VERSION ""

NS_ :

BS_:

BU_:

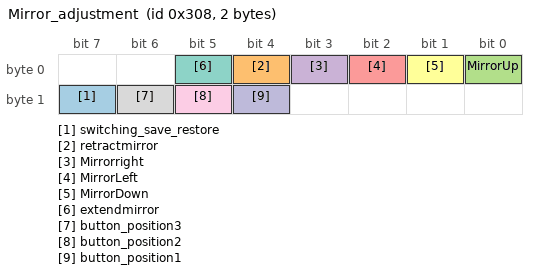
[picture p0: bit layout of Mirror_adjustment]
BO_ 776 Mirror_adjustment: 2 Vector__XXX
 SG_ switching_save_restore : 15|1@1+ (1,0) [0|0] "" Vector__XXX
 SG_ retractmirror : 4|1@1+ (1,0) [0|0] "" Vector__XXX
 SG_ MirrorUp : 0|1@1+ (1,0) [0|0] "" Vector__XXX
 SG_ Mirrorright : 3|1@1+ (1,0) [0|0] "" Vector__XXX
 SG_ MirrorLeft : 2|1@1+ (1,0) [0|0] "" Vector__XXX
 SG_ MirrorDown : 1|1@1+ (1,0) [0|0] "" Vector__XXX
 SG_ extendmirror : 5|1@1+ (1,0) [0|0] "" Vector__XXX
 SG_ button_position3 : 14|1@1+ (1,0) [0|0] "" Vector__XXX
 SG_ button_position2 : 13|1@1+ (1,0) [0|0] "" Vector__XXX
 SG_ button_position1 : 12|1@1+ (1,0) [0|0] "" Vector__XXX
